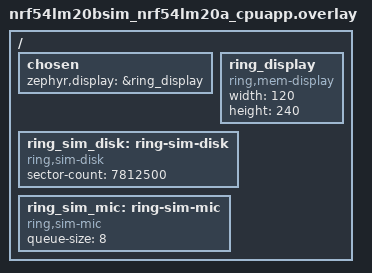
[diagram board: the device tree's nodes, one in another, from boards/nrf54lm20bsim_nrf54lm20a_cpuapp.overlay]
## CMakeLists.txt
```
# Ring OS application.
#
# The ring_core module is added with ZEPHYR_EXTRA_MODULES, only when
# firmware/modules/ring_core/zephyr/module.yml exists. Why not the west
# manifest: ring_core lives in this same repository (the manifest's own
# "self" project), and west lists modules only from separate projects.
# The check on the file lets the app build before that module is delivered.

cmake_minimum_required(VERSION 3.20.0)

set(RING_CORE_DIR ${CMAKE_CURRENT_LIST_DIR}/../modules/ring_core)
if(EXISTS ${RING_CORE_DIR}/zephyr/module.yml)
  list(APPEND ZEPHYR_EXTRA_MODULES ${RING_CORE_DIR})
  message(STATUS "ring_core module: added from ${RING_CORE_DIR}")
else()
  message(STATUS "ring_core module: not present, app builds without it")
endif()

# Step 2: ring_devices (pairing, three devices) and ring_control (keyboard, media
# keys, pointer), added the same way and only when present. Step 3: ring_inbox (the store
# of the last notifications), ring_time (the clock) and ring_iphone (notifications, media,
# time from an iPhone). Step 5: ring_relay (notifications from a helper app on an Android phone, into the same store).
# Step 6: the recorder parts (ring_rhw: driver interfaces and simulated drivers; storage, audio, USB transfer, power,
# motor, system, factory) and the recorder that joins them (ring_recorder).
foreach(RING_MOD ring_devices ring_control ring_inbox ring_time ring_iphone ring_relay ring_glue ring_screens
        ring_rhw ring_store ring_audio ring_xfer ring_power ring_motor ring_sys ring_factory ring_recorder)
  set(RING_MOD_DIR ${CMAKE_CURRENT_LIST_DIR}/../modules/${RING_MOD})
  if(EXISTS ${RING_MOD_DIR}/zephyr/module.yml)
    list(APPEND ZEPHYR_EXTRA_MODULES ${RING_MOD_DIR})
    message(STATUS "${RING_MOD} module: added from ${RING_MOD_DIR}")
  else()
    message(STATUS "${RING_MOD} module: not present, app builds without it")
  endif()
endforeach()

# Step 4: ring_screens (the screens, drawn with LVGL on a memory display until the panel driver exists).

# Step 3: the link and stack settings of the iPhone part live in one file that the test ring includes too.
list(APPEND EXTRA_CONF_FILE ${CMAKE_CURRENT_LIST_DIR}/../modules/ring_iphone/ring_iphone_link.conf)

find_package(Zephyr REQUIRED HINTS $ENV{ZEPHYR_BASE})
project(ring_app)

target_sources(app PRIVATE src/main.c)
```

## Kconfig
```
# Ring OS application options. Later steps add their options here.

config RING_PAIR_WINDOW_AT_BOOT
	bool "Open the pairing window at boot while no device is paired"
	help
	  A stand-in for the pairing screen, which comes with the Screens part:
	  lets the development kit pair with a phone or a computer. The passkey is
	  printed on the console. Off in the product.

source "Kconfig.zephyr"
```

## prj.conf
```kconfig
CONFIG_PRINTK=y
CONFIG_CONSOLE=y

# Step 2: devices and control. Bluetooth peripheral with the HID service,
# one local identity per paired device (three), pairing with a displayed passkey.
CONFIG_MAIN_STACK_SIZE=4096
CONFIG_HEAP_MEM_POOL_SIZE=2048

CONFIG_BT=y
CONFIG_BT_PERIPHERAL=y
CONFIG_BT_DEVICE_NAME="Ring"
CONFIG_BT_DEVICE_APPEARANCE=961
CONFIG_BT_MAX_CONN=1
CONFIG_BT_MAX_PAIRED=3
CONFIG_BT_ID_MAX=3
CONFIG_BT_ATT_TX_COUNT=6
# the Apple and Nordic guidance: no automatic security request, no automatic PHY update
CONFIG_BT_GATT_AUTO_SEC_REQ=n
CONFIG_BT_AUTO_PHY_UPDATE=n
CONFIG_BT_TX_PROCESSOR_STACK_SIZE=1024
CONFIG_BT_SMP=y
CONFIG_BT_SMP_APP_PAIRING_ACCEPT=y
CONFIG_BT_SMP_SC_ONLY=y

CONFIG_BT_CONN_CTX=y
CONFIG_BT_HIDS=y
CONFIG_BT_HIDS_INPUT_REP_MAX=3
CONFIG_BT_HIDS_OUTPUT_REP_MAX=0
CONFIG_BT_HIDS_FEATURE_REP_MAX=0
CONFIG_BT_HIDS_ATTR_MAX=24
CONFIG_BT_HIDS_MAX_CLIENT_COUNT=1
CONFIG_BT_HIDS_DEFAULT_PERM_RW_AUTHEN=y
CONFIG_BT_GATT_UUID16_POOL_SIZE=40
CONFIG_BT_GATT_CHRC_POOL_SIZE=20

CONFIG_RING_CORE=y
CONFIG_RING_DEVICES=y
CONFIG_RING_CONTROL=y
CONFIG_RING_GLUE=y

# Step 3: the iPhone part. The kit's clients for Apple's Notification Center, Media and Current Time
# services and the GATT service (Service Changed) are selected by CONFIG_RING_IPHONE.
CONFIG_RING_INBOX=y
CONFIG_RING_TIME=y
CONFIG_RING_IPHONE=y
# link and stack settings of the iPhone part: modules/ring_iphone/ring_iphone_link.conf (EXTRA_CONF_FILE, app/CMakeLists.txt)

# Step 5: the relay service: a Bluetooth service of the ring that takes notifications from a helper app on an Android phone
# (design/firmware.md 7.7) and puts them in the same store as the iPhone's. Needs no setting of its own: the link settings above are shared.
CONFIG_RING_RELAY=y

# Step 4: the screens. LVGL (the kit's copy) draws in a 240 x 120 frame; the display is the memory display of
# ring_screens (devicetree overlay in boards/) until the panel driver exists.
CONFIG_RING_SCREENS=y
CONFIG_RING_SCREENS_REAL=y
CONFIG_LVGL=y
CONFIG_LV_Z_AUTO_INIT=n
CONFIG_LV_COLOR_DEPTH_16=y
CONFIG_LV_FONT_MONTSERRAT_14=y
CONFIG_LV_FONT_MONTSERRAT_16=y
CONFIG_LV_FONT_MONTSERRAT_28=y
CONFIG_LV_FONT_MONTSERRAT_32=y
CONFIG_LV_Z_MEM_POOL_SIZE=32768
CONFIG_RING_SCREENS_STACK_SIZE=8192

# round 2: static stack frame sizes (-fstack-usage) for tools/stack_report.py
CONFIG_STACK_USAGE=y

# round 2: stacks sized from the static chains of tools/stack_report.py plus a margin (no runtime peak exists: simulated builds run on host stacks)
# step 6: the glue's thread also carries out the recorder's actions (card, sign wait): 4096 (tools/stack_report.py, stage stack-report)
CONFIG_RING_GLUE_STACK_SIZE=4096
CONFIG_BT_RX_STACK_SIZE=2048

# Step 6: the recorder parts and the recorder (design/firmware.md sections 4, 5, 6, 8, 9). The drivers behind them are chosen per
# board (decision D11b): CONFIG_RING_RHW_SIM in boards/nrf54lm20bsim_nrf54lm20a_cpuapp.conf (simulated drivers) and off in the
# development kit build (the real files, unproven: firmware/docs/recorder-notes.md).
CONFIG_RING_RHW=y
CONFIG_RING_STORE=y
CONFIG_RING_AUDIO=y
CONFIG_RING_XFER=y
CONFIG_RING_POWER=y
CONFIG_RING_MOTOR=y
CONFIG_RING_SYS=y
CONFIG_RING_FACTORY=y
CONFIG_RING_RECORDER=y
# the factory part's ship beacon and T-RADIO at 0 dBm (FW l.1031, l.1057), its name from the device id (factory-notes.md section 7)
CONFIG_BT_CTLR_TX_PWR_0=y
CONFIG_HWINFO=y
# USB identity: the vendor and product id in modules/ring_xfer/src/rxf_hw_real.c (0x2fe3, 0x0100) are the kit's test pair,
# NOT FOR SHIPPING; the owner chooses the product's pair (questions_for_owner in docs/recorder-notes.md).
```

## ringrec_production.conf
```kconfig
# The ring's production settings (step 7 fix round 1; design/firmware.md l.1061: "Production builds: no UART output;
# DBG_TX is an input with pull-down"). Added on top of the ring's development settings
# (boards/ringrec_nrf54lm20a_cpuapp.conf) with -Dapp_EXTRA_CONF_FILE, together with the devicetree overlay
# firmware/boards/ringrec/ringrec_production.overlay (uart20 off, DBG_TX an input with pull-down) and, for MCUboot,
# firmware/boards/ringrec/ringrec_production_mcuboot.conf. tools/build_all.sh stage ring-production builds it (compile
# only). The development build keeps its console.
CONFIG_SERIAL=n
CONFIG_CONSOLE=n
CONFIG_UART_CONSOLE=n
```

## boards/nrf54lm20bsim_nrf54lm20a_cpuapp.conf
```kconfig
# Step 6, decision D11b: the simulated chip runs the recorder parts on the simulated drivers of ring_rhw (no card, no
# microphones, no power chip in the simulation). The development kit build has this option off.
CONFIG_RING_RHW_SIM=y
```

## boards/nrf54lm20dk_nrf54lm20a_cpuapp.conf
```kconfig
# Development kit: pairings and the active device survive a reset (Zephyr settings in RRAM).
CONFIG_BT_SETTINGS=y
CONFIG_SETTINGS=y
CONFIG_FLASH=y
CONFIG_FLASH_MAP=y
CONFIG_FLASH_PAGE_LAYOUT=y

# Step 6, decision D11b: the development kit build uses the real driver files of the recorder parts (decision D15: each
# compiles only where its devicetree node exists; none is proven, docs/recorder-notes.md). No simulated driver here.
CONFIG_RING_RHW_SIM=n
# the USB transfer part's real file (device stack "device_next", design/firmware.md 6.1)
CONFIG_USB_DEVICE_STACK_NEXT=y
# the system part's real file (update into slot 1, settings, retained memory, watchdog: docs/sys-notes.md section 6)
CONFIG_WATCHDOG=y
CONFIG_RETAINED_MEM=y
CONFIG_STREAM_FLASH=y
CONFIG_IMG_MANAGER=y
CONFIG_MCUBOOT_IMG_MANAGER=y
```

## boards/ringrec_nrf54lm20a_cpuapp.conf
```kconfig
# The ring (step 7, board ringrec in firmware/boards/ringrec): the development kit's settings
# (nrf54lm20dk_nrf54lm20a_cpuapp.conf) plus what the real driver files need on the ring's devicetree
# (firmware/docs/recorder-notes.md section 6; firmware/docs/board-notes.md). Nothing here is proven on a ring.

# pairings and the active device survive a reset (Zephyr settings in RRAM)
CONFIG_BT_SETTINGS=y
CONFIG_SETTINGS=y
CONFIG_FLASH=y
CONFIG_FLASH_MAP=y
CONFIG_FLASH_PAGE_LAYOUT=y
# settings back end (open point K10, a PROPOSAL for the lead, board-notes.md): ZMS, the SDK's key-value store made
# for RRAM and MRAM as well as flash, on storage_partition (20 KB, design/firmware.md 9.2)
CONFIG_ZMS=y

# decision D11b: the real driver files, no simulated driver
CONFIG_RING_RHW_SIM=n
# the USB transfer part's real file (device stack "device_next", design/firmware.md 6.1)
CONFIG_USB_DEVICE_STACK_NEXT=y
# the system part's real file (update into slot 1, settings, retained memory, watchdog: docs/sys-notes.md section 6)
CONFIG_WATCHDOG=y
CONFIG_RETAINED_MEM=y
CONFIG_STREAM_FLASH=y
CONFIG_IMG_MANAGER=y
CONFIG_MCUBOOT_IMG_MANAGER=y

# the audio part's real file: the kit's PDM driver behind the microphone API (design/firmware.md 4.1)
CONFIG_AUDIO=y
CONFIG_AUDIO_DMIC=y
# the storage part's real file: SD card over SPI through the disk access API (design/firmware.md 5.1)
CONFIG_DISK_ACCESS=y
CONFIG_DISK_DRIVERS=y
CONFIG_DISK_DRIVER_SDMMC=y
# the "sleep" pin states (microphone clock low, storage lines disconnected) exist only with device power management:
# without it Zephyr leaves every "sleep" state out of the build (zephyr/drivers/pinctrl.h, PINCTRL_SKIP_SLEEP), and
# spi00's suspend (rst_hw_real.c) needs it too
CONFIG_PM_DEVICE=y

# the power chip nPM1304 (I2C): the kit's drivers for its regulators (the two load switches) and charger
CONFIG_I2C=y
CONFIG_REGULATOR=y
CONFIG_SENSOR=y
# the power part's real file (modules/ring_power/src/rpw_hw_real.c, CONFIG_RING_POWER_REAL, on by default where the
# nPM1304 node exists) and the kit's fuel gauge library it calls; its calls were fixed to SDK v3.4.2 in step 7 fix
# round 1. The cell model is the board's include/rpw_battery_model.h: NOT THE RING'S CELL (a stand-in).
CONFIG_RING_POWER_REAL=y
CONFIG_NRF_FUEL_GAUGE=y
```

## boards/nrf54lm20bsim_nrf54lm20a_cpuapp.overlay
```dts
/* The ring's panel stands in as a memory display (120 x 240) until the panel driver exists. */
/* Step 6: the simulated card and the simulated microphone input of ring_rhw (bindings ring,sim-disk and ring,sim-mic);
 * the real ones come with the ring's board files (step 7). No chip pin is named here. */
/ {
	chosen {
		zephyr,display = &ring_display;
	};
	ring_display: ring_display {
		compatible = "ring,mem-display";
		width = <120>;
		height = <240>;
	};
	ring_sim_disk: ring-sim-disk {
		compatible = "ring,sim-disk";
		sector-count = <7812500>;
	};
	ring_sim_mic: ring-sim-mic {
		compatible = "ring,sim-mic";
		queue-size = <8>;
	};
};
```

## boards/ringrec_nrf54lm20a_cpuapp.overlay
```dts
/* The ring (step 7, board ringrec in firmware/boards/ringrec). The panel driver does not exist: the screen stays drawn
 * on the memory display (120 x 240) as on the development kit. The panel's bus and control pins are in the board's
 * devicetree (node lcd-dbi on spi21); nothing here names a chip pin. */
/ {
	chosen {
		zephyr,display = &ring_display;
	};
	ring_display: ring_display {
		compatible = "ring,mem-display";
		width = <120>;
		height = <240>;
	};
};
```

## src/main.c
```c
/*
 * Ring OS application.
 * It prints one start line with the application version from app/VERSION
 * and the Zephyr kernel version, starts the devices and control parts
 * (step 2), then sleeps. Step 3 adds the iPhone part (ring_iphone: notifications with their
 * actions, track title and media commands, the time): rglue_init() starts it next to devices and
 * control, so this file has no extra call. Step 5 adds the relay service (ring_relay, design/firmware.md 7.7): a static
 * Bluetooth service plus a start-up hook that registers it with the iPhone part, so this file has no call for it either.
 *
 * Step 2 wiring: rctl_init() registers the HID service, rdev_init() enables
 * Bluetooth and advertises to the active device, rglue_init() starts the core
 * and carries its actions to control and to the recording hook (the same
 * module the two-device tests run). The joystick driver, the screens and the
 * settings menu come later: the driver calls rglue_input() with each debounced
 * switch edge; a control screen calls rctl_set_active(true) while it is shown
 * (control is off at start, so menu moves never type on the host); the screens
 * call rdev_pair_open(), rdev_switch() and rdev_remove() and show the passkey
 * from passkey_show.
 *
 * Step 6 wiring (the recorder, ring_recorder): the core starts in BOOT; every action of the core goes to
 * rrec_action(), every core step ends in rrec_glue_after() (the recorder's step, then the screens), the facts the
 * recorder owns are written in rrec_glue_screen_fact() before each core call, and the core's sign hook is
 * rrec_sign_hook() (decision D1). rrec_init() runs the boot sequence and gives the core "init done".
 */

#include <zephyr/kernel.h>
#include <zephyr/sys/printk.h>
#include <app_version.h>
#include <version.h>

#include <ring_devices/rdev.h>
#include <ring_control/rctl.h>
#include <ring_glue/rglue.h>
#include <ring_screens/rscr.h>
#include <ring_recorder/rrec.h>
#include <rrec_int.h>

static void passkey_show(uint8_t slot, uint32_t passkey)
{
	/* SCR_PAIR shows these six digits; they also go to the console */
	printk("ring-os: pairing passkey for slot %u: %06u\n", slot, passkey);
	rscr_on_passkey(slot, passkey);
}

static void active_changed(uint8_t slot)
{
	printk("ring-os: active device slot %u\n", slot);
	rscr_on_active_changed(slot);
}

static void paired(uint8_t slot)
{
	rscr_on_paired(slot);
}

static void window_closed(void)
{
	rscr_on_window_closed();
}

static void removed(uint8_t slot)
{
	rscr_on_removed(slot);
}

static void link_changed(uint8_t slot, bool up)
{
	ARG_UNUSED(slot);
	ARG_UNUSED(up);
	rscr_poke();
}

static const struct rglue_ops glue_ops = {
	.action = rrec_action,               /* every action of the core, carried out by the recorder (step 6) */
	.after = rrec_glue_after,            /* the recorder's step, then the screens follow every core step */
	.screen_fact = rrec_glue_screen_fact, /* the recorder's facts, then the screens' lock fact: before every core call */
	.sign_start = rrec_sign_hook,        /* decision D1: the core asks for the recording sign before a start */
	.factory_gesture = rrec_factory_gesture, /* FACTORY_TEST: the gestures go to the factory tests (T-JOY, T-CENTRE) */
};

static const struct rdev_callbacks dev_cb = {
	.passkey_show = passkey_show,
	.paired = paired,
	.window_closed = window_closed,
	.removed = removed,
	.active_changed = active_changed,
	.link = link_changed,
};

int main(void)
{
	int err;

	printk("ring-os start: app %s, zephyr %s, board %s\n",
	       APP_VERSION_STRING, KERNEL_VERSION_STRING, CONFIG_BOARD_TARGET);

	err = rctl_init();
	if (err != 0) {
		printk("ring-os: HID service failed %d\n", err);
	} else {
		err = rdev_init(&dev_cb);
		if (err != 0) {
			printk("ring-os: devices failed %d\n", err);
		}
	}
	err = rscr_start(&rscr_real_ops);
	if (err != 0) {
		printk("ring-os: screens failed %d\n", err);
	}
	/* The core starts in BOOT; the recorder's boot sequence gives it "init done" (or "storage init fails"). */
	rglue_init(&glue_ops, RC_ST_BOOT);
	err = rrec_init();
	if (err != 0) {
		printk("ring-os recorder: boot sequence returned %d\n", err);
	}
	/* RECOVERY ends by itself (the recorder's thread scans): wait for a settled state before the boot line */
	for (int i = 0; i < 100 && (rglue_state() == RC_ST_BOOT || rglue_state() == RC_ST_RECOVERY); i++) {
		k_sleep(K_MSEC(10));
	}
	printk("ring-os recorder: boot done, state %s\n", rc_state_name(rglue_state()));
	if (err == 0 && IS_ENABLED(CONFIG_RING_PAIR_WINDOW_AT_BOOT) && rdev_active() == RDEV_NONE) {
		(void)rdev_pair_open(RDEV_ANY, RDEV_PAIR_WINDOW_MS);
	}

	while (1) {
		k_sleep(K_SECONDS(1));
	}

	return 0;
}
```
